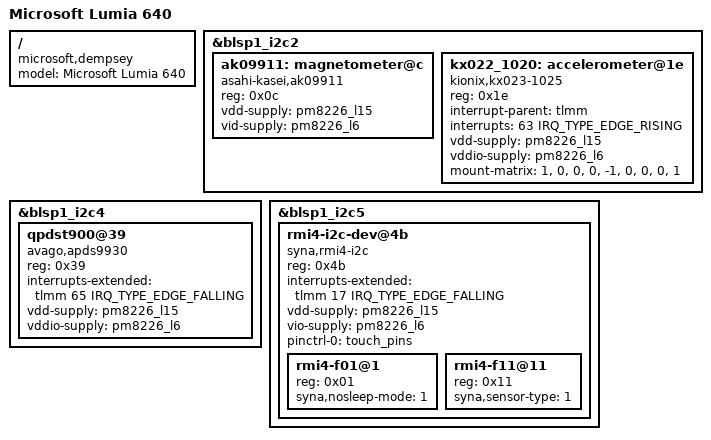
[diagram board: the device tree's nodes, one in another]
// SPDX-License-Identifier: BSD-3-Clause
/*
 * Copyright (c) 2021, Dominik Kobinski <Dominduchami@outlook.com>
 * Copyright (c) 2021, Ivaylo Ivanov <ivo.ivanov@null.net>
 * Copyright (c) 2021, Jack Matthews <jm5112356@gmail.com>
 * Copyright (c) 2022, Rayyan Ansari <rayyan@ansari.sh>
 */
/dts-v1/;

#include "qcom-msm8226-microsoft-common.dtsi"

/ {
	model = "Microsoft Lumia 640";
	compatible = "microsoft,dempsey","qcom,msm8226";
};

&blsp1_i2c2 {
    status = "okay";

    ak09911: magnetometer@c {
		compatible = "asahi-kasei,ak09911";
		reg = <0x0c>;

		vdd-supply = <&pm8226_l15>;
		vid-supply = <&pm8226_l6>;
	};

    kx022_1020: accelerometer@1e {
        /*
         * This is actually the Kionix KX022-1020, but the KX023-1025 driver
         * seems to work fine for now.
         */
        compatible = "kionix,kx023-1025";
        reg = <0x1e>;

        interrupt-parent = <&tlmm>;
        interrupts = <63 IRQ_TYPE_EDGE_RISING>;

        vdd-supply = <&pm8226_l15>;
        vddio-supply = <&pm8226_l6>;

        mount-matrix =  "1",  "0",  "0",
                        "0", "-1",  "0",
                        "0",  "0",  "1";
    };
};

&blsp1_i2c4 {
 	status = "okay";

 	qpdst900@39 {
  		compatible = "avago,apds9930";
   		reg = <0x39>;

   		interrupts-extended = <&tlmm 65 IRQ_TYPE_EDGE_FALLING>;

   		vdd-supply = <&pm8226_l15>;
   		vddio-supply = <&pm8226_l6>;

  	};
};

&blsp1_i2c5 {
	status = "okay";

	rmi4-i2c-dev@4b {
		compatible = "syna,rmi4-i2c";
		reg = <0x4b>;
		#address-cells = <1>;
		#size-cells = <0>;

		interrupts-extended = <&tlmm 17 IRQ_TYPE_EDGE_FALLING>;
		vdd-supply = <&pm8226_l15>;
		vio-supply = <&pm8226_l6>;

		pinctrl-names = "default";
		pinctrl-0 = <&touch_pins>;

		rmi4-f01@1 {
			reg = <0x01>;
			syna,nosleep-mode = <1>;
		};

		rmi4-f11@11 {
			reg = <0x11>;
			syna,sensor-type = <1>;
		};
	};
};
